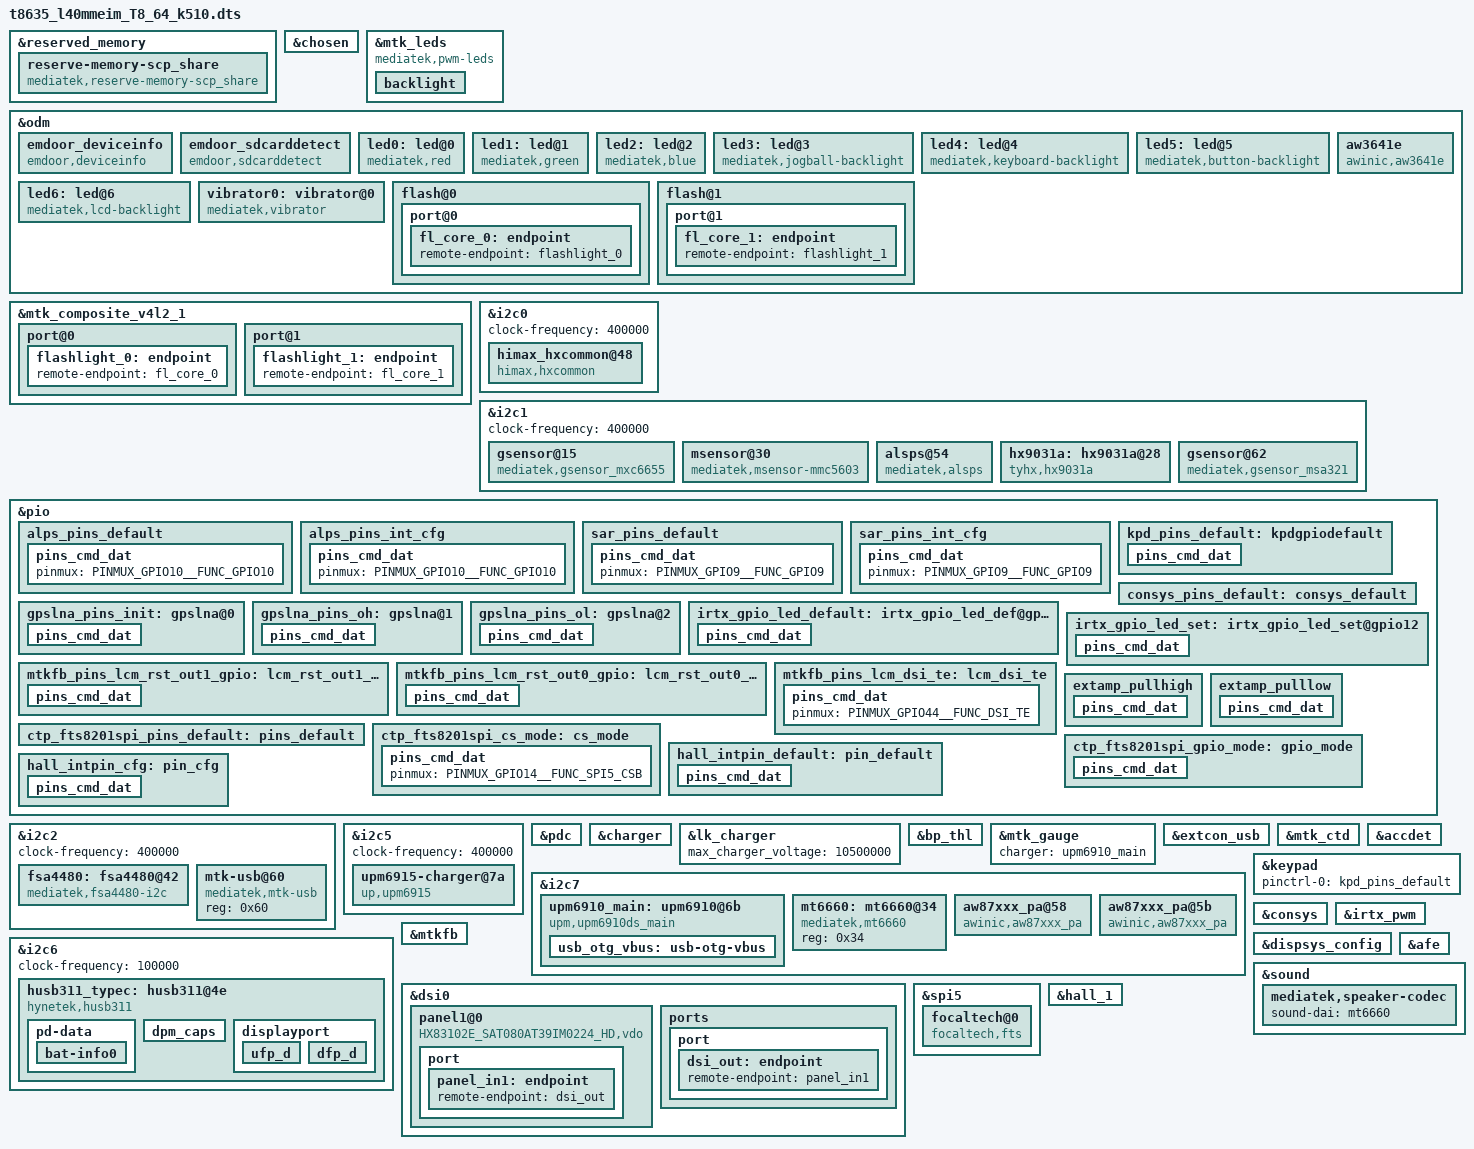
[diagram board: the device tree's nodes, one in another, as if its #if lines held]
// SPDX-License-Identifier: GPL-2.0
/*
 * Copyright (c) 2019 MediaTek Inc.
 */

/dts-v1/;
/plugin/;
#include <dt-bindings/interrupt-controller/irq.h>
#include <dt-bindings/interrupt-controller/arm-gic.h>
#include <dt-bindings/pinctrl/mt6768-pinfunc.h>

#include <mediatek/bat_setting/t8635_31101100PL_5000mAh.dtsi>

&reserved_memory {
	reserve-memory-scp_share {
		compatible = "mediatek,reserve-memory-scp_share";
		no-map;
		size = <0 0x00d00000>;
		alignment = <0 0x1000000>;
		alloc-ranges = <0 0x40000000 0 0x50000000>;
	};
};

/* chosen */
&chosen {

	atag,videolfb-fb_base_l = <0x7e605000>;
	atag,videolfb-fb_base_h = <0x0>;
	atag,videolfb-islcmfound = <1>;
	atag,videolfb-islcm_inited = <0>;
	atag,videolfb-fps= <6000>;
	atag,videolfb-vramSize= <0x017e8000>;
	atag,videolfb-lcmname=
		"hx83112b_fhdp_dsi_cmd_auo_rt5081_drv";
};

&mtk_leds {
	compatible = "mediatek,pwm-leds";
	backlight {
		led_mode = <5>;
		pwms = <&disp_pwm 0 39385>;
		pwm-names = "lcd-backlight";
		pwm_config = <0 3 0 0 0>;
	};
};

&odm {
	emdoor_deviceinfo:emdoor_deviceinfo{
		compatible = "emdoor,deviceinfo";
		sdcard_dect-gpios = <&pio 178 0>;
		ddr-name =
			"RS1G32LV4D2BDS_53BT_CNFV_4DIE",
			"RS1G32LV4D2BDS_53BT_B3SE_2DIE",
			"K4UBE3D4AM_SGCL";
		status = "okay";
	};
	emdoor_sdcarddetect:emdoor_sdcarddetect{
		compatible = "emdoor,sdcarddetect";
		status = "okay";
	};
	led0:led@0 {
		compatible = "mediatek,red";
		led_mode = <0>;
		data = <1>;
		pwm_config = <0 0 0 0 0>;
	};
	led1:led@1 {
		compatible = "mediatek,green";
		led_mode = <0>;
		data = <1>;
		pwm_config = <0 0 0 0 0>;
	};
	led2:led@2 {
		compatible = "mediatek,blue";
		led_mode = <0>;
		data = <1>;
		pwm_config = <0 0 0 0 0>;
	};
	led3:led@3 {
		compatible = "mediatek,jogball-backlight";
		led_mode = <0>;
		data = <1>;
		pwm_config = <0 0 0 0 0>;
	};
	led4:led@4 {
		compatible = "mediatek,keyboard-backlight";
		led_mode = <0>;
		data = <1>;
		pwm_config = <0 0 0 0 0>;
	};
	led5:led@5 {
		compatible = "mediatek,button-backlight";
		led_mode = <0>;
		data = <1>;
		pwm_config = <0 0 0 0 0>;
	};
	led6:led@6 {
		compatible = "mediatek,lcd-backlight";
		led_mode = <5>;
		data = <1>;
		pwm_config = <0 3 0 0 0>;
	};
	vibrator0:vibrator@0 {
		compatible = "mediatek,vibrator";
		vib_timer = <25>;
		vib_limit = <9>;
		vib_vol= <9>;
	};
	/* aw3641e flash  */
	aw3641e:aw3641e {
		compatible = "awinic,aw3641e";
		flash-en-gpio = <&pio 160 0>;
		flash-sel-gpio = <&pio 153 0>;
		status = "okay";
	};
	flash@0{
		reg = <0>;
		type = <0>;
		ct = <0>;
		part = <0>;
		port@0 {
			fl_core_0: endpoint {
				remote-endpoint = <&flashlight_0>;
			};
		};
	};
	flash@1{
		reg = <1>;
		type = <0>;
		ct = <1>;
		part = <0>;
		port@1 {
			fl_core_1: endpoint {
				remote-endpoint = <&flashlight_1>;
			};
		};
	};
};

&mtk_composite_v4l2_1 {
	port@0 {
		flashlight_0: endpoint {
			remote-endpoint = <&fl_core_0>;
		};
	};
	port@1 {
		flashlight_1: endpoint {
			remote-endpoint = <&fl_core_1>;
		};
	};
};

&i2c0 {
	status = "okay";
	clock-frequency = <400000>;

	himax_hxcommon@48 {
		compatible = "himax,hxcommon";
		himax,irq-gpio = <&pio 1 0x0>;
		himax,rst-gpio = <&pio 23 0x0>;
		himax,panel-coords = <0 800 0 1280>;
		himax,display-coords = <0 800 0 1280>;
		reg = <0x48>;
		status = "okay";
	};
};

&i2c1 {
	clock-frequency = <400000>;

	//start mxc6655 gsensor
	gsensor@15 {
		compatible = "mediatek,gsensor_mxc6655";
		reg = <0x15>;
		i2c_num = <1>;
		i2c_addr = <0x15 0 0 0>;
		direction = <4>;
		//4.6.
		power_id = <0xffff>;
		power_vol = <0>;
		firlen = <0>;
		is_batch_supported = <0>;
		status = "okay";
	};
	//end mxc6655	

	msensor@30 {	/*mmc5603*/
		compatible = "mediatek,msensor-mmc5603";
		reg = <0x30>;
		i2c_num				= <1>;
		i2c_addr			= <0x30 0 0 0>;
		direction			= <0>;
		power_id			= <0xffff>;
		power_vol			= <0>;
		is_batch_supported		= <0>;
	};
	
	alsps@54 {
		compatible = "mediatek,alsps";
		pinctrl-names = "default","alps_pins_int_cfg";
		pinctrl-0 = <&alps_pins_default>;
		pinctrl-1 = <&alps_pins_int_cfg>;
		reg = <0x54>;
		i2c_num = <1>;
		i2c_addr = <0x54 0x00 0x00 0x00>;
		polling_mode_ps = <0>;
		polling_mode_als = <1>;
		power_id = <0xffff>;
		power_vol = <0>;
		als_level = <200 400 600 800 1000 1200 1400 1600 3000 4000 6000 7000 8000 9000 10000>;
		als_value = <10 50 100 150 200 250 280 280 1600 1600 1600 6000 6000 9000 10240 10240>;
		ps_threshold_high = <120>;
		ps_threshold_low = <100>;
		is_batch_supported_ps = <0>;
		is_batch_supported_als = <0>;
		interrupt-parent = <&pio>;
		interrupts = <10 IRQ_TYPE_LEVEL_LOW 10 0>;
		int-gpio = <&pio 10 0>;
	};

	hx9031a: hx9031a@28 {
		compatible = "tyhx,hx9031a";
		reg = <0x28>;
		pinctrl-names = "default","sar_pins_int_cfg";
		pinctrl-0 = <&sar_pins_default>;
		pinctrl-1 = <&sar_pins_int_cfg>;
		interrupt-parent = < &pio >;
		interrupts = <9 IRQ_TYPE_LEVEL_LOW 9 0>;
		tyhx,irq-gpio = <&pio 9 0x0>;
		tyhx,irq-flags = <2>; //1:rising 2:falling
		tyhx,channel-flag = <0x7>;
		//tyhx,power-supply-type =<1>;	//power config
		status = "okay";
	};
	
	gsensor@62 {
		compatible = "mediatek,gsensor_msa321";
		reg = <0x62>;
		i2c_num = <1>;
		i2c_addr = <0x15 0 0 0>;
		direction = <1>;
		//4.6.
		power_id = <0xffff>;
		power_vol = <0>;
		firlen = <0>;
		is_batch_supported = <0>;
		status = "okay";
	};	
};

/* ALSPS GPIO standardization */
&pio {
	alps_pins_default: alps_pins_default {
		pins_cmd_dat {
			pinmux = <PINMUX_GPIO10__FUNC_GPIO10>;
		};
	};
	
	alps_pins_int_cfg: alps_pins_int_cfg {
		pins_cmd_dat {
			pinmux = <PINMUX_GPIO10__FUNC_GPIO10>;
		};
	};
};
/* Sar Sensor GPIO standardization */
&pio {
	sar_pins_default: sar_pins_default {
		pins_cmd_dat {
			pinmux = <PINMUX_GPIO9__FUNC_GPIO9>;
		};
	};

	sar_pins_int_cfg: sar_pins_int_cfg {
		pins_cmd_dat {
			pinmux = <PINMUX_GPIO9__FUNC_GPIO9>;
		};
	};
};

&i2c2 {
	clock-frequency = <400000>;

	fsa4480: fsa4480@42 {
		compatible = "mediatek,fsa4480-i2c";
		reg = <0x42>;
		fsa4480,en_pin = <&pio 21 0>;
		status = "okay";
	};
	
	mtk-usb@60 {
		compatible = "mediatek,mtk-usb";
		reg = <0x60>;
		status = "okay";
	};
};

&i2c5 {
	status = "okay";	
	clock-frequency = <400000>;
	upm6915-charger@7a {
		compatible = "up,upm6915";
		reg = <0x7a>;/*real is 0x6a*/
		up,cd-gpio = <&pio 79 0>;
		// up,otg-gpio = <&pio 3 GPIO_ACTIVE_HIGH>;
		charger_name = "secondary_chg";

		up,upm6915,usb-vindpm = <4600>;
		up,upm6915,usb-vreg = <4180>;
		up,upm6915,weak-vbat = <3400>;
		up,upm6915,termination-current = <180>;
		up,upm6915,boost-current = <1200>;
		up,upm6915,vac-ovp-threshold = <14000>;
		up,upm6915,auto-reset-32sec;
	};

};
&pdc {
		min_charger_voltage = <4600000>;
		pd_vbus_low_bound = <5000000>;
		pd_vbus_upper_bound = <9000000>;
		vsys_watt = <5000000>;
		ibus_err = <14>;

		pd_stop_battery_soc = <95>;

		/* single charger */
		sc_input_current = <3200000>;
		sc_charger_current = <3000000>;

		/* dual charger in series*/
		dcs_chg1_input_current = <1000000>;
		dcs_chg2_input_current = <1000000>;
		dcs_chg1_charger_current = <2000000>;
		dcs_chg2_charger_current = <2000000>;

		/* dual charger */
		dual_polling_ieoc = <160000>;
		slave_mivr_diff = <100000>;
		vbat_threshold = <4450>;
};
&charger {
	charger = <&upm6910_main>;
	battery_cv = <4400000>;
	/* charging current */
	usb_charger_current = <500000>;
	ac_charger_current = <3900000>;
	ac_charger_input_current = <2000000>;
	charging_host_charger_current = <1500000>;

	max_charger_voltage = <10500000>;
	charger_configuration= <1>;
	/* dynamic mivr */
	enable_dynamic_mivr;
	min_charger_voltage_1 = <4600000>;
	min_charger_voltage_2 = <4600000>;
	max_dmivr_charger_current = <1800000>;

	/* sw jeita */
	/*enable_sw_jeita;*/
	jeita_temp_above_t4_cv = <4100000>;
	jeita_temp_t3_to_t4_cv = <4100000>;
	jeita_temp_t2_to_t3_cv = <4400000>;
	jeita_temp_t1_to_t2_cv = <4400000>;
	jeita_temp_t0_to_t1_cv = <4400000>;
	jeita_temp_below_t0_cv = <4400000>;

	jeita_temp_above_t4_cc = <3500000>;
	jeita_temp_t3_to_t4_cc = <3500000>;
	jeita_temp_t2_to_t3_cc = <3500000>;
	jeita_temp_t1_to_t2_cc = <1400000>;
	jeita_temp_t0_to_t1_cc = <1400000>;
	jeita_temp_below_t0_cc = <1400000>;

	temp_t4_thres = <60>;
	temp_t4_thres_minus_x_degree = <58>;
	temp_t3_thres = <45>;
	temp_t3_thres_minus_x_degree = <43>;
	temp_t2_thres = <15>;
	temp_t2_thres_plus_x_degree = <17>;
	temp_t1_thres = <5>;
	temp_t1_thres_plus_x_degree = <7>;
	temp_t0_thres = <0>;
	temp_t0_thres_plus_x_degree = <2>;
	temp_neg_10_thres = <0>;
	/* battery temperature protection */
	enable_min_charge_temp;
	min_charge_temp = <0>;
	min_charge_temp_plus_x_degree = <2>;
	max_charge_temp = <55>;
	max_charge_temp_minus_x_degree = <50>;
};

&lk_charger {
	max_charger_voltage = <10500000>;
};

&bp_thl {
	soc_limit = <0>;
	soc_limit_ext = <5>;
	soc_limit_ext_release = <15>;
};

&mtk_gauge {
	charger = <&upm6910_main>;
};

&extcon_usb {
	status= "okay";
	vbus-supply = <&usb_otg_vbus>;
	vbus-voltage;
	vbus-current;
	charger = <&upm6910_main>;
};

&mtk_ctd {
	bc12 = <&upm6910_main>;
	bc12_sel = <0>;
};

&i2c7 {
	upm6910_main: upm6910@6b {
		status = "okay";
		clock-frequency = <400000>;
		compatible = "upm,upm6910ds_main";
		reg = <0x6b>;

		upm6910x_main,intr_gpio = <&pio 20 IRQ_TYPE_EDGE_FALLING>;
		charger_name = "primary_chg";
		upm,upm6910,usb-vlim = <4700>;
		upm,upm6910,usb-ilim = <2000>;
		upm,upm6910,usb-vreg = <4400>;
		upm,upm6910,usb-ichg = <2000>;
		upm,upm6910,precharge-current = <180>;
		upm,upm6910,termination-current = <180>;/*normal 5V 2A*/
		upm,upm6910,boost-voltage = <5300>;
		upm,upm6910,boost-current = <500>;
		upm,upm6910,vac-ovp-threshold = <14000>;

		usb_otg_vbus: usb-otg-vbus {
			regulator-compatible = "usb-otg-vbus";
			regulator-name = "usb-otg-vbus";
			regulator-min-microvolt = <5000000>;
			regulator-max-microvolt = <5000000>;
		};
	};
};

&i2c6 {
	clock-frequency = <100000>;

	husb311_typec: husb311@4e {
		compatible = "hynetek,husb311";
		reg = <0x4e>;
		status = "okay";
		
		interrupt-parent = <&pio>;
		//interrupts = <41 0x8>;
		tcpc-dual,supported_modes = <0>; /* 0: dfp/ufp, */
						 /* 1: dfp, 2: ufp */
		tcpc,name = "type_c_port0"; /* tcpc_device's name */
		tcpc,role_def = <4>; /* 0: SNK Only, 1: SRC Only, 2: DRP, */
					/* 3: Try.SRC, 4: Try.SNK */
		tcpc,rp_level = <2>; /* 0: Default, 1: 1.5, 2: 3.0 */
		tcpc,vconn_supply  = <0>;  /* 0: Never, 1: Always, */
					      /* 2: EMarkOnly, 3: StartOnly */
#if (CONFIG_MTK_GAUGE_VERSION == 30)
		tcpc,notifier_supply_num = <3>;
#else
		tcpc,notifier_supply_num = <2>;
#endif
		husb311pd,intr_gpio = <&pio 5 0x0>;
		husb311pd,intr_gpio_num = <5>;

		charger = <&upm6910_main>;

		pd-data {
			pd,vid = <0x2e99>;
			pd,pid = <0x0311>;
			pd,source-cap-ext = <0x171129cf 0x00000000 0x00000000
					     0x00000000 0x00000000 0x02000000>;
			pd,mfrs = "HynetekTCPC";

			/*
			 *	VSAFE5V = 0, MAX_POWER = 1, CUSTOM = 2,
			 *	MAX_POWER_LV = 0x21, MAX_POWER_LVIC = 0x31
			 *	MAX_POWER_HV = 0x41, MAX_POWER_HVIC = 0x51
			 */
			pd,charging_policy = <0x31>;

			/*
			 * Fixed 5V, 500 mA <0x00019032>
			 * Fixed 5V, 1A <0x00019064>
			 * Fixed 5V, 2A <0x000190c8>
			 * Fixed 5V, 3A <0x0001912c>
			 * Fixed 9V, 500 mA <0x0002d032>
			 * Fixed 9V, 1A <0x0002d064>
			 * Fixed 9V, 2A <0x0002d0c8>
			 * Fixed 9V, 3A <0x0002d12c>
			 * Fixed 12V,2A <0x0003c0c8>
			 * Variable 5-9V, 1A <0x8642d064>
			 * Variable 5-9V, 2A <0x8642d0c8>
			 * Variable 5-9V, 3A <0x8642d12c>
			 * PPS 3V~5.9V, 3A <0xC0761E3C>
			 */
			pd,source-pdo-size = <1>;
			pd,source-pdo-data = <0x00019032>;
			pd,sink-pdo-size = <1>;
			pd,sink-pdo-data = <0x0002d0c8>;

			/*
			 * No DP, host + device
			 *	pd,id-vdo-size = <3>;
			 *	pd,id-vdo-data = <0xd10029cf 0x0 0x17110000>;
			 * With DP
			 *	pd,id-vdo-size = <3>;
			 *	pd,id-vdo-data = <0xd60029cf 0x0 0x17110000
			 */

			pd,id-vdo-size = <3>;
			pd,id-vdo-data = <0xd10029cf 0x0 0x17110000>;

			bat,nr = <1>;
			pd,country_nr = <0>;

			bat-info0 {
				bat,vid = <0x29cf>;
				bat,pid = <0x1711>;
				bat,mfrs = "bat1";
				bat,design_cap = <3000>;
			};

			//bat-info1 {
			//	bat,vid = <0x8abc>;
			//	bat,pid = <0x5234>;
			//	bat,mfrs = "bat2";
			//	bat,design_cap = <4000>;
			//};

			//country0 {
			//	pd,country_code = <0x5457>;
			//	pd,country_len = <2>; /* max len = 26 */
			//	pd,country_data = <0xff 0xff>;
			//};

			//country1 {
			//	pd,country_code = <0x5553>;
			//	pd,country_len = <3>; /* max len = 26 */
			//	pd,country_data = <0xf1 0xf2 0xf3>;
			//};
		};
		dpm_caps {
			local_dr_power;
			local_dr_data;
			//local_ext_power;
			local_usb_comm;
			//local_usb_suspend;
			//local_high_cap;
			//local_give_back;
			local_no_suspend;
			local_vconn_supply;

			//attemp_discover_cable_dfp;
			attemp_enter_dp_mode;
			attemp_discover_cable;
			attemp_discover_id;

			/* 0: disable, 1: prefer_snk, 2: prefer_src */
			pr_check = <0>;
			//pr_reject_as_source;
			//pr_reject_as_sink;
			//pr_check_gp_source;
			//pr_check_gp_sink;

			/* 0: disable, 1: prefer_ufp, 2: prefer_dfp */
			dr_check = <0>;
			//dr_reject_as_dfp;
			//dr_reject_as_ufp;
		};
		displayport {
			/* connection type = "both", "ufp_d", "dfp_d" */
			1st_connection = "dfp_d";
			2nd_connection = "dfp_d";
			signal,dp_v13;
			//signal,dp_gen2;
			usbr20_not_used;
			typec,receptacle;
			ufp_d {
				//pin_assignment,mode_a;
				//pin_assignment,mode_b;
				//pin_assignment,mode_c;
				//pin_assignment,mode_d;
				//pin_assignment,mode_e;
			};
			dfp_d {
				/* Only support mode C & D */
				//pin_assignment,mode_a;
				//pin_assignment,mode_b;
				pin_assignment,mode_c;
				pin_assignment,mode_d;
				pin_assignment,mode_e;
				pin_assignment,mode_f;
			};
		};
	};
};


/* accdet start */
&accdet {
	/* accdet micbias voltage: 0x07,2.7v;0x05,2.5v;0x02,1.9v */
	accdet-mic-vol = <6>;
	headset-mode-setting = <0x500 0x500 1 0x1f0 0x800 0x800 0x20 0x44>;
	accdet-plugout-debounce = <1>;
	/*1:ACC mode, 2:low cost without in bias, 6:low cost with in bias*/
	accdet-mic-mode = <1>;
	/* eint_level_trigger: 8,LEVEL_LOW(DEF) ;4,LV_HIGH;others,LV_LOW */
	headset-eint-level-pol = <8>;
	/*0--MD_MAX--UP_MAX--DW_MAX*/
	headset-three-key-threshold = <0 80 220 400>;
	headset-three-key-threshold-CDD = <0 121 192 600>;
	/*0--MD_MAX--VOICE_MAX--UP_MAX--DW_MAX*/
	headset-four-key-threshold = <0 58 121 192 400>;
	status = "okay";
};
/* accdet end */

/* keypad start */
&keypad {
	pinctrl-names = "default";
	pinctrl-0 = <&kpd_pins_default>;
};

&pio {
	kpd_pins_default: kpdgpiodefault {
		pins_cmd_dat {
			pinmux = <PINMUX_GPIO93__FUNC_KPCOL0>;
			bias-pull-up = <MTK_PUPD_SET_R1R0_10>;
			input-enable;
			input-schmitt-enable;
		};
	};
};
/* keypad end */

/* CONSYS GPIO standardization */
&pio {
	consys_pins_default: consys_default {
	};
	gpslna_pins_init: gpslna@0 {
		pins_cmd_dat {
			pinmux = <PINMUX_GPIO94__FUNC_GPIO94>;
			slew-rate = <0>;
			bias-disable;
			output-low;
		};
	};
	gpslna_pins_oh: gpslna@1 {
		pins_cmd_dat {
			pinmux = <PINMUX_GPIO94__FUNC_GPIO94>;
			slew-rate = <1>;
			output-high;
		};
	};
	gpslna_pins_ol: gpslna@2 {
		pins_cmd_dat {
			pinmux = <PINMUX_GPIO94__FUNC_GPIO94>;
			slew-rate = <1>;
			output-low;
		};
	};
};
&consys {
	pinctrl-names = "default", "gps_lna_state_init",
		"gps_lna_state_oh", "gps_lna_state_ol";
	pinctrl-0 = <&consys_pins_default>;
	pinctrl-1 = <&gpslna_pins_init>;
	pinctrl-2 = <&gpslna_pins_oh>;
	pinctrl-3 = <&gpslna_pins_ol>;
	status = "okay";
};
/* CONSYS end */

/* IRTX GPIO Start */
&irtx_pwm {
	pinctrl-names = "irtx_gpio_led_default", "irtx_gpio_led_set";
	pinctrl-0 = <&irtx_gpio_led_default>;
	pinctrl-1 = <&irtx_gpio_led_set>;
	status = "okay";
};
&pio {
	/* IRTX GPIO Settings -Start */
	/* default: GPIO0, output, high */
	irtx_gpio_led_default:irtx_gpio_led_def@gpio12 {
		pins_cmd_dat {
			pinmux = <PINMUX_GPIO12__FUNC_GPIO12>;
			slew-rate = <1>;
			bias-disable;
			output-low;
			input-schmitt-enable = <0>;
		};
	};

	irtx_gpio_led_set:irtx_gpio_led_set@gpio12 {
		pins_cmd_dat {
			pinmux = <PINMUX_GPIO12__FUNC_PWM0>;
			slew-rate = <1>;
			output-high;
		};
	};
}; /* IRTX GPIO Settings -End */

/* DISPSYS GPIO standardization */
&pio {
	mtkfb_pins_lcm_rst_out1_gpio: lcm_rst_out1_gpio {
		pins_cmd_dat {
			pinmux = <PINMUX_GPIO45__FUNC_GPIO45>;
			slew-rate = <1>;
			output-high;
		};
	};

	mtkfb_pins_lcm_rst_out0_gpio: lcm_rst_out0_gpio {
		pins_cmd_dat {
			pinmux = <PINMUX_GPIO45__FUNC_GPIO45>;
			slew-rate = <1>;
			output-low;
		};
	};

	mtkfb_pins_lcm_dsi_te: lcm_dsi_te {
		pins_cmd_dat {
			pinmux = <PINMUX_GPIO44__FUNC_DSI_TE>;
		};
	};
};

&mtkfb {
	pinctrl-names =
		"lcm_rst_out1_gpio", "lcm_rst_out0_gpio",
		"mode_te_te";
	pinctrl-0 = <&mtkfb_pins_lcm_rst_out1_gpio>;
	pinctrl-1 = <&mtkfb_pins_lcm_rst_out0_gpio>;
	pinctrl-2 = <&mtkfb_pins_lcm_dsi_te>;
	status = "okay";
};

&dispsys_config {
	pinctrl-names =
		"lcm_rst_out1_gpio", "lcm_rst_out0_gpio",
		"mode_te_te";
	pinctrl-0 = <&mtkfb_pins_lcm_rst_out1_gpio>;
	pinctrl-1 = <&mtkfb_pins_lcm_rst_out0_gpio>;
	pinctrl-2 = <&mtkfb_pins_lcm_dsi_te>;
	status = "okay";
};

//-------------------------------------------------------------------------------//
//LCM_RST   ------------接ah26脚 GPIO45
//AE24(169) --- GPIO_LCM_BIAS_EP --- LCM_OUTP    --- AVDD   VSP
//J23(158)  --- GPIO_LCM_BIAS_EN --- LCM_OUTN    --- AVEE   VSN
//LCD_VDD18_EN ： 控制LCD_1P8 电压输出， 接 j22 脚 GPIO159   IOVCC
//
//-------------------------------------------------------------------------------//

&dsi0 {
	status = "okay";
	#address-cells = <1>;
	#size-cells = <0>;
	panel1@0 {
		compatible = "HX83102E_SAT080AT39IM0224_HD,vdo";
		reg = <0>;
		reset-gpios = <&pio 45 0>;
		vdd_en-gpios = <&pio 24 0>;
		bias-gpios = <&pio 169 0>, <&pio 165 0>;
		pinctrl-names = "default";
		port {
			panel_in1: endpoint {
				remote-endpoint = <&dsi_out>;
			};
		};
	};
	ports {
		port {
			dsi_out: endpoint {
				remote-endpoint = <&panel_in1>;
			};
		};
	};
};

&i2c7 {
	mt6660: mt6660@34 {
		compatible = "mediatek,mt6660";
		#sound-dai-cells = <0>;
		reg = <0x34>;
		status = "okay";
	};
	
	//tom add for aw87xxx
	aw87xxx_pa@58 {
		compatible = "awinic,aw87xxx_pa";
		reg = <0x58>;
		//无 reset-pin 的产品不能配置 reset-gpio，否则无法正常加载配置
		reset-gpio = <&pio 25 0>;
		dev_index = < 0 >; //第 1 个 PA dev_index 为 0
		status = "okay";
	};
	aw87xxx_pa@5b {
		compatible = "awinic,aw87xxx_pa";
		reg = <0x5b>;
		//无 reset-pin 的产品不能配置 reset-gpio，否则无法正常加载配置
		reset-gpio = <&pio 27 0>;
		dev_index = < 1 >; //第 2 个 PA dev_index 为 1
		status = "okay";
	};		
	//end	
};


//--------------------------------------------------------------------------------------------//
// AUDIO start
&afe {
       pinctrl-names = "extamp-pullhigh", "extamp-pulllow";
       pinctrl-0 = <&extamp_pullhigh>;
       pinctrl-1 = <&extamp_pulllow>;
       status = "okay";
};
//control PA pin for on and off
&pio {
       extamp_pullhigh: extamp_pullhigh {
               pins_cmd_dat {
                       pinmux = <PINMUX_GPIO150__FUNC_GPIO150>;
                       slew-rate = <1>;
                       output-high;
               };
       };
       extamp_pulllow: extamp_pulllow {
               pins_cmd_dat {
                       pinmux = <PINMUX_GPIO150__FUNC_GPIO150>;
                       slew-rate = <1>;
                       output-low;
               };
       };
};
//--------------------------------------------------------------------------------------------//

&sound {
	//ext-amp-gpio = <&pio 150 0>;
	ext-amp-gpio = <&pio 158 0>;
	pa_mode = <3>;
	mediatek,speaker-codec {
		sound-dai = <&mt6660>;
	};
};

/* DISPSYS GPIO standardization end*/

/* TOUCH start */
&pio {
    ctp_fts8201spi_pins_default: pins_default {
    };

    ctp_fts8201spi_cs_mode: cs_mode {
        pins_cmd_dat {
            pinmux = <PINMUX_GPIO14__FUNC_SPI5_CSB>;
        };
    };
    ctp_fts8201spi_gpio_mode: gpio_mode {
        pins_cmd_dat {
            pinmux = <PINMUX_GPIO14__FUNC_GPIO14>;
            slew-rate = <1>;
            output-low;
        };
    };
};

&spi5 {
    status = "okay";
    #address-cells = <1>;
    #size-cells = <0>;
    focaltech@0 {
        compatible = "focaltech,fts";
        reg = <0x0>;
        spi-max-frequency = <6000000>;
        interrupt-parent = <&pio>;
        interrupts = <1 IRQ_TYPE_EDGE_FALLING 1 0>;
        //focaltech,reset-gpio = <&pio 23 0>;
        //focaltech,irq-gpio = <&pio 1 02>;
        focaltech,max-touch-number = <10>;
        focaltech,display-coords =  <0 0 1200 1920>;
        status = "okay";

        pinctrl-names = "pins_default", "cs_mode", "gpio_mode";
        pinctrl-0 = <&ctp_fts8201spi_pins_default>;
        pinctrl-1 = <&ctp_fts8201spi_cs_mode>;
        pinctrl-2 = <&ctp_fts8201spi_gpio_mode>;
    };
};
/* TOUCH end */

/* Hall start */
&pio {
	hall_intpin_default: pin_default {
		pins_cmd_dat {
			pinmux = <PINMUX_GPIO8__FUNC_GPIO8>;
			output-high;
		};
	};
	hall_intpin_cfg: pin_cfg {
		pins_cmd_dat {
			pinmux = <PINMUX_GPIO8__FUNC_GPIO8>;
			input-enable;
		};
	};

};

&hall_1 {
	status = "okay";

	pinctrl-names = "pin_default", "pin_cfg";
	pinctrl-0 = <&hall_intpin_default>;
	pinctrl-1 = <&hall_intpin_cfg>;

	interrupt-parent = <&pio>;
	interrupts = <8 IRQ_TYPE_LEVEL_LOW 8 0>;
	gpio_det_level_hall_pin1 = <&pio 8 0>;
};
/* Hall end */

&accdet {
	//this pin using for SGM7237BYUWQ10G/TR switch, 8635 not use
	gpio_typec_earphone = <&pio 55 0>;
	status = "okay";
};

//#include "mediatek/chipone_tddi_9551.dtsi"
#include <t8635_l40mmeim_T8_64_k510/cust.dtsi>
#include "mediatek/cust_t8635_l40mmeim_T8_64_k510_camera.dtsi"
/*End of this file, DO NOT ADD ANYTHING HERE*/
